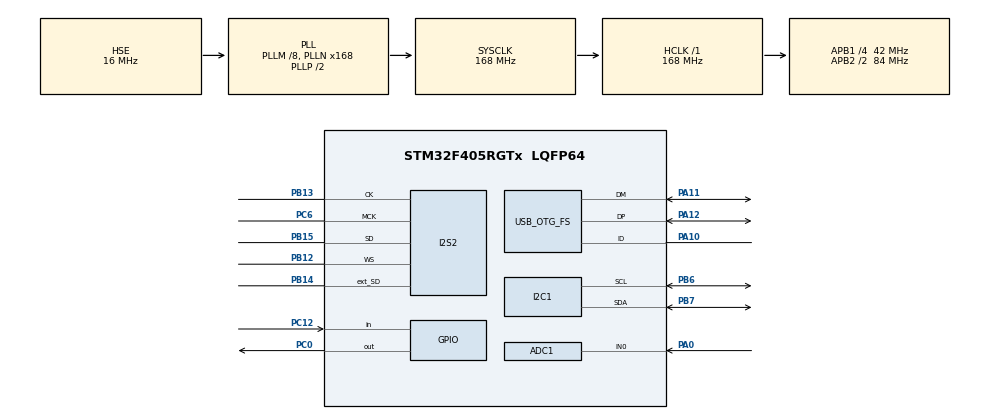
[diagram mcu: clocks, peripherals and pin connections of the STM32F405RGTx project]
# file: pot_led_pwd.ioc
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ADC1.Channel-0\#ChannelRegularConversion=ADC_CHANNEL_0
ADC1.ClockPrescaler=ADC_CLOCK_SYNC_PCLK_DIV8
ADC1.ContinuousConvMode=DISABLE
ADC1.NbrOfConversionFlag=1
ADC1.Rank-0\#ChannelRegularConversion=1
ADC1.SamplingTime-0\#ChannelRegularConversion=ADC_SAMPLETIME_3CYCLES
ADC1.master=1
Dma.I2S2_EXT_RX.1.Direction=DMA_PERIPH_TO_MEMORY
Dma.I2S2_EXT_RX.1.FIFOMode=DMA_FIFOMODE_DISABLE
Dma.I2S2_EXT_RX.1.Instance=DMA1_Stream3
Dma.I2S2_EXT_RX.1.MemDataAlignment=DMA_MDATAALIGN_HALFWORD
Dma.I2S2_EXT_RX.1.MemInc=DMA_MINC_ENABLE
Dma.I2S2_EXT_RX.1.Mode=DMA_CIRCULAR
Dma.I2S2_EXT_RX.1.PeriphDataAlignment=DMA_PDATAALIGN_HALFWORD
Dma.I2S2_EXT_RX.1.PeriphInc=DMA_PINC_DISABLE
Dma.I2S2_EXT_RX.1.Priority=DMA_PRIORITY_VERY_HIGH
Dma.Request0=SPI2_TX
Dma.Request1=I2S2_EXT_RX
Dma.SPI2_TX.0.Direction=DMA_MEMORY_TO_PERIPH
Dma.SPI2_TX.0.FIFOMode=DMA_FIFOMODE_DISABLE
Dma.SPI2_TX.0.Instance=DMA1_Stream4
Dma.SPI2_TX.0.MemDataAlignment=DMA_MDATAALIGN_HALFWORD
Dma.SPI2_TX.0.MemInc=DMA_MINC_ENABLE
Dma.SPI2_TX.0.Mode=DMA_CIRCULAR
Dma.SPI2_TX.0.PeriphDataAlignment=DMA_PDATAALIGN_HALFWORD
Dma.SPI2_TX.0.PeriphInc=DMA_PINC_DISABLE
Dma.SPI2_TX.0.Priority=DMA_PRIORITY_VERY_HIGH
I2S2.AudioFreq=I2S_AUDIOFREQ_48K
I2S2.ErrorAudioFreq=-2.34 %
I2S2.FullDuplexMode=I2S_FULLDUPLEXMODE_ENABLE
I2S2.Instance=SPI$Index
I2S2.RealAudioFreq=46.875 KHz
I2S2.VirtualMode=I2S_MODE_MASTER
Mcu.Family=STM32F4
Mcu.Name=STM32F405RGTx
Mcu.Package=LQFP64
NVIC.DMA1_Stream3_IRQn=true\:0\:0\:false\:false\:true\:false\:true\:true
NVIC.DMA1_Stream4_IRQn=true\:0\:0\:false\:false\:true\:false\:true\:true
NVIC.PriorityGroup=NVIC_PRIORITYGROUP_4
NVIC.TIM2_IRQn=true\:0\:0\:false\:false\:true\:true\:true\:true
PA0-WKUP.Signal=ADCx_IN0
PA10.Mode=OTG/Dual_Role_Device
PA10.Signal=USB_OTG_FS_ID
PA11.Mode=OTG/Dual_Role_Device
PA11.Signal=USB_OTG_FS_DM
PA12.Mode=OTG/Dual_Role_Device
PA12.Signal=USB_OTG_FS_DP
PA13.Mode=Serial_Wire
PA13.Signal=SYS_JTMS-SWDIO
PA14.Mode=Serial_Wire
PA14.Signal=SYS_JTCK-SWCLK
PB12.Mode=Full_Duplex_Master
PB12.Signal=I2S2_WS
PB13.Mode=Full_Duplex_Master
PB13.Signal=I2S2_CK
PB14.Mode=Full_Duplex_Master
PB14.Signal=I2S2_ext_SD
PB15.Mode=Full_Duplex_Master
PB15.Signal=I2S2_SD
PB6.Mode=I2C
PB6.Signal=I2C1_SCL
PB7.Mode=I2C
PB7.Signal=I2C1_SDA
PC0.Signal=GPIO_Output
PC12.Signal=GPIO_Input
PC6.Mode=Master_Clock_Activated
PC6.Signal=I2S2_MCK
PH0-OSC_IN.Mode=HSE-External-Oscillator
PH0-OSC_IN.Signal=RCC_OSC_IN
PH1-OSC_OUT.Mode=HSE-External-Oscillator
PH1-OSC_OUT.Signal=RCC_OSC_OUT
ProjectManager.HeapSize=0x200
ProjectManager.StackSize=0x400
ProjectManager.TargetToolchain=STM32CubeIDE
RCC.48MHZClocksFreq_Value=48000000
RCC.AHBFreq_Value=168000000
RCC.APB1CLKDivider=RCC_HCLK_DIV4
RCC.APB1Freq_Value=42000000
RCC.APB1TimFreq_Value=84000000
RCC.APB2CLKDivider=RCC_HCLK_DIV2
RCC.APB2Freq_Value=84000000
RCC.APB2TimFreq_Value=168000000
RCC.CortexFreq_Value=168000000
RCC.HCLKFreq_Value=168000000
RCC.HSE_VALUE=16000000
RCC.HSI_VALUE=16000000
RCC.LSE_VALUE=32768
RCC.PLLM=8
RCC.PLLN=168
RCC.PLLQ=7
RCC.SYSCLKFreq_VALUE=168000000
RCC.SYSCLKSource=RCC_SYSCLKSOURCE_PLLCLK
RCC.VCOOutputFreq_Value=336000000
SH.ADCx_IN0.0=ADC1_IN0,IN0
TIM2.AutoReloadPreload=TIM_AUTORELOAD_PRELOAD_ENABLE
TIM2.Channel-Output\ Compare1\ No\ Output=TIM_CHANNEL_1
TIM2.OC1Preload=ENABLE
TIM2.Period=999
TIM2.Prescaler=167
TIM2.Pulse-Output\ Compare1\ No\ Output=20
VP_TIM2_VS_ClockSourceINT.Mode=Internal
VP_TIM2_VS_no_output1.Mode=Output Compare1 No Output
board=custom

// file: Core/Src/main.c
/* USER CODE BEGIN Header */
/**
  ******************************************************************************
  * @file           : main.c
  * @brief          : Main program body
  ******************************************************************************
  * @attention
  *
  * Copyright (c) 2025 STMicroelectronics.
  * All rights reserved.
  *
  * This software is licensed under terms that can be found in the LICENSE file
  * in the root directory of this software component.
  * If no LICENSE file comes with this software, it is provided AS-IS.
  *
  ******************************************************************************
  */
/* USER CODE END Header */
#include "main.h"

ADC_HandleTypeDef hadc1;

I2C_HandleTypeDef hi2c1;

I2S_HandleTypeDef hi2s2;
DMA_HandleTypeDef hdma_spi2_tx;
DMA_HandleTypeDef hdma_i2s2_ext_rx;

TIM_HandleTypeDef htim2;

void SystemClock_Config(void);
static void MX_GPIO_Init(void);
static void MX_DMA_Init(void);
static void MX_USB_OTG_FS_USB_Init(void);
static void MX_I2S2_Init(void);
static void MX_ADC1_Init(void);
static void MX_I2C1_Init(void);
static void MX_TIM2_Init(void);

int main(void)
{

  /* MCU Configuration--------------------------------------------------------*/

  /* Reset of all peripherals, Initializes the Flash interface and the Systick. */
  HAL_Init();

  /* Configure the system clock */
  SystemClock_Config();

  /* Initialize all configured peripherals */
  MX_GPIO_Init();
  MX_DMA_Init();
  MX_USB_OTG_FS_USB_Init();
  MX_I2S2_Init();
  MX_ADC1_Init();
  MX_I2C1_Init();
  MX_TIM2_Init();
  /* USER CODE BEGIN 2 */

  // Enable interrupt for both when CNT=CCR1 and when CNT reloads to create PWM
  HAL_TIM_Base_Start_IT(&htim2);
  HAL_TIM_OC_Start_IT(&htim2, TIM_CHANNEL_1);
  __HAL_RCC_TIM2_CLK_ENABLE();

  /* USER CODE END 2 */

  /* Infinite loop */
  /* USER CODE BEGIN WHILE */

  // Store ADC pot reading and CCR1 value for TIM2 CH1 OC
  uint32_t adc_reading;
  int ccr1;
  while (1)
  {
	// Poll ADC once per loop
	HAL_ADC_Start(&hadc1);
	HAL_ADC_PollForConversion(&hadc1, HAL_MAX_DELAY);
	adc_reading = HAL_ADC_GetValue(&hadc1);

	// Convert 12-bit ADC value to a 7-bit range of 0 to 127. This gives a duty
	// cycle range of 0% to 12.7% which looks good on the LED.
	ccr1 = adc_reading >> 5;
	__HAL_TIM_SET_COMPARE(&htim2, TIM_CHANNEL_1, ccr1);

    /* USER CODE END WHILE */

  }
}

void SystemClock_Config(void)
{
  RCC_OscInitTypeDef RCC_OscInitStruct = {0};
  RCC_ClkInitTypeDef RCC_ClkInitStruct = {0};

  /** Configure the main internal regulator output voltage
  */
  __HAL_RCC_PWR_CLK_ENABLE();
  __HAL_PWR_VOLTAGESCALING_CONFIG(PWR_REGULATOR_VOLTAGE_SCALE1);

  /** Initializes the RCC Oscillators according to the specified parameters
  * in the RCC_OscInitTypeDef structure.
  */
  RCC_OscInitStruct.OscillatorType = RCC_OSCILLATORTYPE_HSE;
  RCC_OscInitStruct.HSEState = RCC_HSE_ON;
  RCC_OscInitStruct.PLL.PLLState = RCC_PLL_ON;
  RCC_OscInitStruct.PLL.PLLSource = RCC_PLLSOURCE_HSE;
  RCC_OscInitStruct.PLL.PLLM = 8;
  RCC_OscInitStruct.PLL.PLLN = 168;
  RCC_OscInitStruct.PLL.PLLP = RCC_PLLP_DIV2;
  RCC_OscInitStruct.PLL.PLLQ = 7;
  if (HAL_RCC_OscConfig(&RCC_OscInitStruct) != HAL_OK)
  {
    Error_Handler();
  }

  /** Initializes the CPU, AHB and APB buses clocks
  */
  RCC_ClkInitStruct.ClockType = RCC_CLOCKTYPE_HCLK|RCC_CLOCKTYPE_SYSCLK
                              |RCC_CLOCKTYPE_PCLK1|RCC_CLOCKTYPE_PCLK2;
  RCC_ClkInitStruct.SYSCLKSource = RCC_SYSCLKSOURCE_PLLCLK;
  RCC_ClkInitStruct.AHBCLKDivider = RCC_SYSCLK_DIV1;
  RCC_ClkInitStruct.APB1CLKDivider = RCC_HCLK_DIV4;
  RCC_ClkInitStruct.APB2CLKDivider = RCC_HCLK_DIV2;

  if (HAL_RCC_ClockConfig(&RCC_ClkInitStruct, FLASH_LATENCY_5) != HAL_OK)
  {
    Error_Handler();
  }
}

static void MX_ADC1_Init(void)
{

  ADC_ChannelConfTypeDef sConfig = {0};

  /** Configure the global features of the ADC (Clock, Resolution, Data Alignment and number of conversion)
  */
  hadc1.Instance = ADC1;
  hadc1.Init.ClockPrescaler = ADC_CLOCK_SYNC_PCLK_DIV8;
  hadc1.Init.Resolution = ADC_RESOLUTION_12B;
  hadc1.Init.ScanConvMode = DISABLE;
  hadc1.Init.ContinuousConvMode = DISABLE;
  hadc1.Init.DiscontinuousConvMode = DISABLE;
  hadc1.Init.ExternalTrigConvEdge = ADC_EXTERNALTRIGCONVEDGE_NONE;
  hadc1.Init.ExternalTrigConv = ADC_SOFTWARE_START;
  hadc1.Init.DataAlign = ADC_DATAALIGN_RIGHT;
  hadc1.Init.NbrOfConversion = 1;
  hadc1.Init.DMAContinuousRequests = DISABLE;
  hadc1.Init.EOCSelection = ADC_EOC_SINGLE_CONV;
  if (HAL_ADC_Init(&hadc1) != HAL_OK)
  {
    Error_Handler();
  }

  /** Configure for the selected ADC regular channel its corresponding rank in the sequencer and its sample time.
  */
  sConfig.Channel = ADC_CHANNEL_0;
  sConfig.Rank = 1;
  sConfig.SamplingTime = ADC_SAMPLETIME_3CYCLES;
  if (HAL_ADC_ConfigChannel(&hadc1, &sConfig) != HAL_OK)
  {
    Error_Handler();
  }

}

static void MX_I2C1_Init(void)
{

  hi2c1.Instance = I2C1;
  hi2c1.Init.ClockSpeed = 100000;
  hi2c1.Init.DutyCycle = I2C_DUTYCYCLE_2;
  hi2c1.Init.OwnAddress1 = 0;
  hi2c1.Init.AddressingMode = I2C_ADDRESSINGMODE_7BIT;
  hi2c1.Init.DualAddressMode = I2C_DUALADDRESS_DISABLE;
  hi2c1.Init.OwnAddress2 = 0;
  hi2c1.Init.GeneralCallMode = I2C_GENERALCALL_DISABLE;
  hi2c1.Init.NoStretchMode = I2C_NOSTRETCH_DISABLE;
  if (HAL_I2C_Init(&hi2c1) != HAL_OK)
  {
    Error_Handler();
  }

}

static void MX_I2S2_Init(void)
{

  hi2s2.Instance = SPI2;
  hi2s2.Init.Mode = I2S_MODE_MASTER_TX;
  hi2s2.Init.Standard = I2S_STANDARD_PHILIPS;
  hi2s2.Init.DataFormat = I2S_DATAFORMAT_16B;
  hi2s2.Init.MCLKOutput = I2S_MCLKOUTPUT_ENABLE;
  hi2s2.Init.AudioFreq = I2S_AUDIOFREQ_48K;
  hi2s2.Init.CPOL = I2S_CPOL_LOW;
  hi2s2.Init.ClockSource = I2S_CLOCK_PLL;
  hi2s2.Init.FullDuplexMode = I2S_FULLDUPLEXMODE_ENABLE;
  if (HAL_I2S_Init(&hi2s2) != HAL_OK)
  {
    Error_Handler();
  }

}

static void MX_TIM2_Init(void)
{

  TIM_ClockConfigTypeDef sClockSourceConfig = {0};
  TIM_MasterConfigTypeDef sMasterConfig = {0};
  TIM_OC_InitTypeDef sConfigOC = {0};

  htim2.Instance = TIM2;
  htim2.Init.Prescaler = 167;
  htim2.Init.CounterMode = TIM_COUNTERMODE_UP;
  htim2.Init.Period = 999;
  htim2.Init.ClockDivision = TIM_CLOCKDIVISION_DIV1;
  htim2.Init.AutoReloadPreload = TIM_AUTORELOAD_PRELOAD_ENABLE;
  if (HAL_TIM_Base_Init(&htim2) != HAL_OK)
  {
    Error_Handler();
  }
  sClockSourceConfig.ClockSource = TIM_CLOCKSOURCE_INTERNAL;
  if (HAL_TIM_ConfigClockSource(&htim2, &sClockSourceConfig) != HAL_OK)
  {
    Error_Handler();
  }
  if (HAL_TIM_OC_Init(&htim2) != HAL_OK)
  {
    Error_Handler();
  }
  sMasterConfig.MasterOutputTrigger = TIM_TRGO_RESET;
  sMasterConfig.MasterSlaveMode = TIM_MASTERSLAVEMODE_DISABLE;
  if (HAL_TIMEx_MasterConfigSynchronization(&htim2, &sMasterConfig) != HAL_OK)
  {
    Error_Handler();
  }
  sConfigOC.OCMode = TIM_OCMODE_TIMING;
  sConfigOC.Pulse = 20;
  sConfigOC.OCPolarity = TIM_OCPOLARITY_HIGH;
  sConfigOC.OCFastMode = TIM_OCFAST_DISABLE;
  if (HAL_TIM_OC_ConfigChannel(&htim2, &sConfigOC, TIM_CHANNEL_1) != HAL_OK)
  {
    Error_Handler();
  }
  __HAL_TIM_ENABLE_OCxPRELOAD(&htim2, TIM_CHANNEL_1);

}

static void MX_USB_OTG_FS_USB_Init(void)
{

}

static void MX_DMA_Init(void)
{

  /* DMA controller clock enable */
  __HAL_RCC_DMA1_CLK_ENABLE();

  /* DMA interrupt init */
  /* DMA1_Stream3_IRQn interrupt configuration */
  HAL_NVIC_SetPriority(DMA1_Stream3_IRQn, 0, 0);
  HAL_NVIC_EnableIRQ(DMA1_Stream3_IRQn);
  /* DMA1_Stream4_IRQn interrupt configuration */
  HAL_NVIC_SetPriority(DMA1_Stream4_IRQn, 0, 0);
  HAL_NVIC_EnableIRQ(DMA1_Stream4_IRQn);

}

static void MX_GPIO_Init(void)
{
  GPIO_InitTypeDef GPIO_InitStruct = {0};

  /* GPIO Ports Clock Enable */
  __HAL_RCC_GPIOH_CLK_ENABLE();
  __HAL_RCC_GPIOC_CLK_ENABLE();
  __HAL_RCC_GPIOA_CLK_ENABLE();
  __HAL_RCC_GPIOB_CLK_ENABLE();

  /*Configure GPIO pin Output Level */
  HAL_GPIO_WritePin(GPIOC, GPIO_PIN_0, GPIO_PIN_RESET);

  /*Configure GPIO pin : PC0 */
  GPIO_InitStruct.Pin = GPIO_PIN_0;
  GPIO_InitStruct.Mode = GPIO_MODE_OUTPUT_PP;
  GPIO_InitStruct.Pull = GPIO_NOPULL;
  GPIO_InitStruct.Speed = GPIO_SPEED_FREQ_LOW;
  HAL_GPIO_Init(GPIOC, &GPIO_InitStruct);

  /*Configure GPIO pins : PA10 PA11 PA12 */
  GPIO_InitStruct.Pin = GPIO_PIN_10|GPIO_PIN_11|GPIO_PIN_12;
  GPIO_InitStruct.Mode = GPIO_MODE_AF_PP;
  GPIO_InitStruct.Pull = GPIO_NOPULL;
  GPIO_InitStruct.Speed = GPIO_SPEED_FREQ_VERY_HIGH;
  GPIO_InitStruct.Alternate = GPIO_AF10_OTG_FS;
  HAL_GPIO_Init(GPIOA, &GPIO_InitStruct);

  /*Configure GPIO pin : PC12 */
  GPIO_InitStruct.Pin = GPIO_PIN_12;
  GPIO_InitStruct.Mode = GPIO_MODE_INPUT;
  GPIO_InitStruct.Pull = GPIO_NOPULL;
  HAL_GPIO_Init(GPIOC, &GPIO_InitStruct);

}

void Error_Handler(void)
{
  __disable_irq();
  while (1)
  {
  }
}
